# ATSAMG55G19 register map
Vendor: Atmel; Series: SAMG55; File version: 0
CPU: CM4 r0p1, selectable endian, MPU, FPU, 4 interrupt priority bits
Registers are 32-bit, read-write, reset 0x0 unless marked. A register's access mark holds for its fields unless they carry their own. Offsets are from the block's base; [hi:lo] are bit positions; {n}, {i} and the like mark numbered series; 'fields as' and 'values as' point back to an identical list.

## SUPC — Supply Controller
Base 0x400E1410; register names take the prefix SUPC_
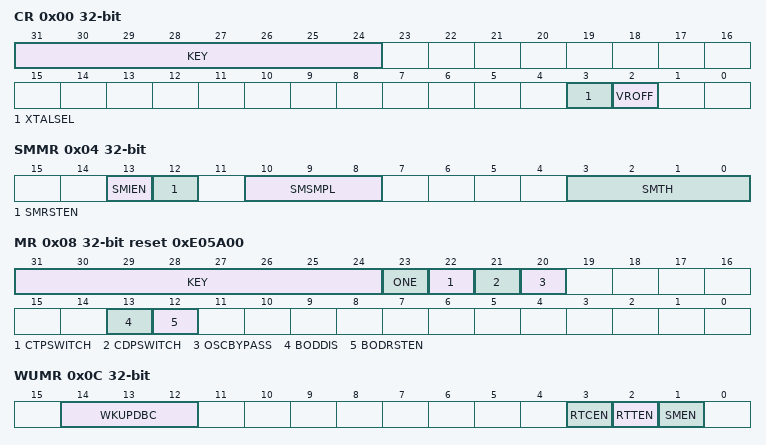
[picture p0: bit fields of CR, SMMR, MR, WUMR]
0x00 CR wo reset not defined — Supply Controller Control Register
  [31:24] KEY — Password
    165=PASSWD (Writing any other value in this field aborts the write operation.Always reads as 0.)
  [3] XTALSEL — Crystal Oscillator Select
    0=NO_EFFECT; 1=CRYSTAL_SEL (If KEY is correct, switches the slow clock on the crystal oscillator output.)
  [2] VROFF — Voltage Regulator Off
    0=NO_EFFECT; 1=STOP_VREG (If KEY is correct, asserts the system reset signal and stops the voltage regulator.)
0x04 SMMR — Supply Controller Supply Monitor Mode Register
  [13] SMIEN — Supply Monitor Interrupt Enable
    0=NOT_ENABLE (The SUPC interrupt signal is not affected when a supply monitor detection occurs.); 1=ENABLE (The SUPC interrupt signal is asserted when a supply monitor detection occurs.)
  [12] SMRSTEN — Supply Monitor Reset Enable
    0=NOT_ENABLE (The core reset signal vddcore_nreset is not affected when a supply monitor detection occurs.); 1=ENABLE (The core reset signal vddcore_nreset is asserted when a supply monitor detection occurs.)
  [10:8] SMSMPL — Supply Monitor Sampling Period
    0=SMD (Supply Monitor disabled); 1=CSM (Continuous Supply Monitor); 2=32SLCK (Supply Monitor enables one SLCK period every 32 SLCK periods); 3=256SLCK (Supply Monitor enables one SLCK period every 256 SLCK periods); 4=2048SLCK (Supply Monitor enables one SLCK period every 2,048 SLCK periods)
  [3:0] SMTH — Supply Monitor Threshold
0x08 MR reset 0xE05A00 — Supply Controller Mode Register
  [31:24] KEY — Password Key
    values as CR.KEY
  [23] ONE — This bit must always be set to 1.
  [22] CTPSWITCH — Cache Tag SRAM Power Switch
    0=OFF (The cache tag SRAM is not powered.); 1=ON (The cache tag SRAM is powered.)
  [21] CDPSWITCH — Cache Data SRAM Power Switch
    0=OFF (The cache data SRAM is not powered.); 1=ON (The cache data SRAM is powered.)
  [20] OSCBYPASS — Oscillator Bypass
    0=NO_EFFECT (No effect. Clock selection depends on XTALSEL value.); 1=BYPASS (The 32 kHz crystal oscillator is selected and put in bypass mode.)
  [13] BODDIS — POR Core Disable
    0=ENABLE (The core brownout detector is enabled.); 1=DISABLE (The core brownout detector is disabled.)
  [12] BODRSTEN — POR Core Reset Enable
    0=NOT_ENABLE (The core reset signal vddcore_nreset is not affected when a brownout detection occurs.); 1=ENABLE (The core reset signal vddcore_nreset is asserted when a brownout detection occurs.)
0x0C WUMR — Supply Controller Wake-up Mode Register
  [14:12] WKUPDBC — Wake-up Inputs Debouncer Period
    0=IMMEDIATE (Immediate, no debouncing, detected active at least on one Slow Clock edge.); 1=3_SCLK (WKUPx shall be in its active state for at least 3 SLCK periods); 2=32_SCLK (WKUPx shall be in its active state for at least 32 SLCK periods); 3=512_SCLK (WKUPx shall be in its active state for at least 512 SLCK periods); 4=4096_SCLK (WKUPx shall be in its active state for at least 4,096 SLCK periods); 5=32768_SCLK (WKUPx shall be in its active state for at least 32,768 SLCK periods)
  [3] RTCEN — Real-time Clock Wake-up Enable
    1=ENABLE (The RTC alarm signal forces the wake-up of the core power supply.)
  [2] RTTEN — Real-time Timer Wake-up Enable
    1=ENABLE (The RTT alarm signal forces the wake-up of the core power supply.)
  [1] SMEN — Supply Monitor Wake-up Enable
    0=NOT_ENABLE (The supply monitor detection has no wake-up effect.); 1=ENABLE (The supply monitor detection forces the wake-up of the core power supply.)
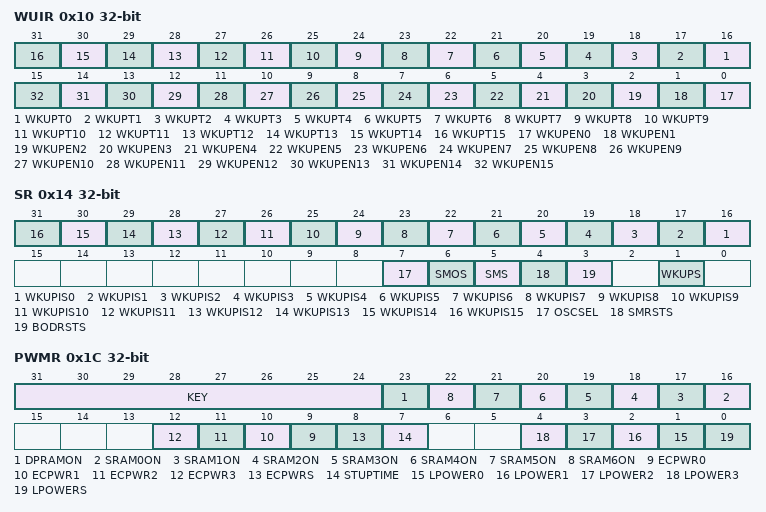
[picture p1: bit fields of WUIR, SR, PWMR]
0x10 WUIR — Supply Controller Wake-up Inputs Register
  [n+16] WKUPT{n} (n=0..15) — Wake-up Input Type {n}
    0=LOW (A low level for a period defined by WKUPDBC on the corresponding wake-up input forces the wake-up of the core power supply.); 1=HIGH (A high level for a period defined by WKUPDBC on the corresponding wake-up input forces the wake-up of the core power supply.)
  [n] WKUPEN{n} (n=0..15) — Wake-up Input Enable {n}
    0=DISABLE (The corresponding wake-up input has no wake-up effect.); 1=ENABLE (The corresponding wake-up input forces the wake-up of the core power supply.)
0x14 SR ro — Supply Controller Status Register
  [n+16] WKUPIS{n} (n=0..15) — WKUP Input Status {n}
    0=DISABLED (The corresponding wake-up input is disabled, or was inactive at the time the debouncer triggered a wake-up event.); 1=ENABLED (The corresponding wake-up input was active at the time the debouncer triggered a wake-up event.)
  [7] OSCSEL — 32-kHz Oscillator Selection Status
    0=RC (The slow clock SLCK is generated by the embedded 32 kHz RC oscillator.); 1=CRYST (The slow clock SLCK is generated by the 32 kHz crystal oscillator.)
  [6] SMOS — Supply Monitor Output Status
    0=HIGH (The supply monitor detected VDDIO higher than its threshold at its last measurement.); 1=LOW (The supply monitor detected VDDIO lower than its threshold at its last measurement.)
  [5] SMS — Supply Monitor Status
    0=NO (No supply monitor detection since the last read of SUPC_SR.); 1=PRESENT (At least one supply monitor detection since the last read of SUPC_SR.)
  [4] SMRSTS — Supply Monitor Reset Status
    0=NO (No supply monitor detection has generated a core reset since the last read of the SUPC_SR.); 1=PRESENT (At least one supply monitor detection has generated a core reset since the last read of the SUPC_SR.)
  [3] BODRSTS — Brownout Detector Reset Status
    0=NO (No core brownout rising edge event has been detected since the last read of the SUPC_SR.); 1=PRESENT (At least one brownout output rising edge event has been detected since the last read of the SUPC_SR.)
  [1] WKUPS — WKUP Wake-up Status
    0=NO (No wake-up due to the assertion of the WKUP pins has occurred since the last read of SUPC_SR.); 1=PRESENT (At least one wake-up due to the assertion of the WKUP pins has occurred since the last read of SUPC_SR.)
0x1C PWMR — Supply Controller Power Mode Register
  [31:24] KEY — Password Key
    90=PASSWD (Writing any other value in this field aborts the write operation.Always reads as 0.)
  [23] DPRAMON — Dual-port RAM Power Control
    0=OFF (USB dual-port RAM is not powered.); 1=ON (USB dual-port RAM is powered.)
  [n+16] SRAM{n}ON (n=0..6) — SRAM Power Control
    0=OFF (SRAMx is not powered.); 1=ON (SRAMx is powered.)
  [n+9] ECPWR{n} (n=0..3) — Enhanced Custom Power Value
  [8] ECPWRS — Enhanced Custom Power Value Selection
    0=FACTORY (The trimming value applied to the regulator when the device is in active mode. This value is factory-defined.); 1=USER (The trimming value applied to the regulator is defined by the value programmed in ECPWRx bits.)
  [7] STUPTIME — Start-up Time when Resuming from Wait Mode
    0=FAST (Fast start-up.); 1=SLOW (Slow start-up.)
  [n+1] LPOWER{n} (n=0..3) — Low Power Value
  [0] LPOWERS — Low Power Value Selection
    0=FACTORY (The trimming value applied to the regulator when the device is in wait mode. This value is factory-defined.); 1=USER (The trimming value applied to the regulator is defined by the value programmed in the LPOWERx bits.)
